# PIC32CX0525SG12144 register map
Vendor: Microchip Technology; Series: 0525SG12; File version: 0
CPU: CM4 r1p0, little endian, no MPU, no FPU, 3 interrupt priority bits, 172 interrupts
Registers are 32-bit, read-write, reset 0x0 unless marked. A register's access mark holds for its fields unless they carry their own. Offsets are from the block's base; [hi:lo] are bit positions.

## PS2_0 — The four PS/2 Ports implementation eliminates the need to bit bang I/O ports to generate PS/2 traffic
Base 0x40009000; register names take the prefix PS2_
Same registers: PS2_1 0x40009040
0x00 TX_DATA wo — Writes to bits 7:0 of this register start a transmission of the data in this register to the peripheral
0x00 RX_DATA ro reset 0xFF — Data received from a peripheral are recorded in this register in bits 7:0.
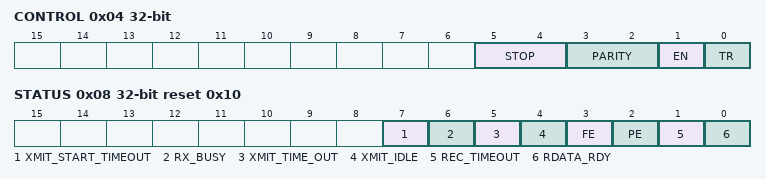
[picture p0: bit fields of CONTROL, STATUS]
0x04 CONTROL — PS2 Control Register
  [5:4] STOP — 00b=Receiver expects an active high stop bit. 01b=Receiver expects an active low stop bit. 10b=Receiver ignores the level of the Stop bit (11th bit is not interpreted as a stop bit). 11b=Reserved.
  [3:2] PARITY — 00b=Receiver expects Odd Parity (default). 01b=Receiver expects Even Parity. 10b=Receiver ignores level of the parity bit (10th bit is not interpreted as a parity bit). 11b=Reserved
  [1] EN — PS/2 Enable. 0=The PS/2 state machine is disabled. 1=The PS/2 state machine is enabled.
  [0] TR — PS/2 Transmit/Receive. 0=The P2/2 channel is enabled to receive data. 1=The PS2 channel is enabled to transmit data.
0x08 STATUS reset 0x10 — PS2 Status Register
  [7] XMIT_START_TIMEOUT — Transmit Start Timeout. 0=No transmit start timeout detected. 1=A start bit was not received within 25 ms following the transmit start event. The transmit start bit time-out condition is also indicated by the XMIT_TIMEOUT bit.
  [6] RX_BUSY — Receive Channel Busy. 0=The channel is idle. 1=The channel is actively receiving PS/2 data
  [5] XMIT_TIME_OUT — Transmitter Time-out. When the XMIT_TIMEOUT bit is set, the PS2_T/R bit is held clear, the PS/2 channel's CLK line is pulled low for a minimum of 300us until the PS/2 Status register is read.
  [4] XMIT_IDLE — Transmitter Idle. 0=The channel is actively transmitting PS/2 data. 1=The channel is not transmitting. A low to high transition on this bit generates a PS2 Activity interrupt.
  [3] FE — Framing Error
  [2] PE — Parity Error
  [1] REC_TIMEOUT — Receive Timeout. The REC_TIMEOUT bit is cleared when the Status Register is read. A low to high transition on this bit generates a PS2 Activity interrupt. (R/WC)
  [0] RDATA_RDY — Receive Data Ready. Reading the Receive Register clears this bit. A low to high transition on this bit generates a PS2 Activity interrupt.

## TFDP — The TFDP serially transmits EC-originated diagnostic vectors to an external debug trace system.
Base 0x40008C00
0x00 MSDATA 8-bit — Debug data to be shifted out on the TFDP Debug port. While data is being shifted out, the Host Interface will 'hold-off' additional writes to the data register until the transfer is complete.
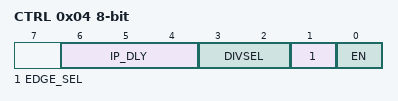
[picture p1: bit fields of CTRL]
0x04 CTRL 8-bit — Debug Control Register
  [6:4] IP_DLY — Inter-packet Delay. The delay is in terms of TFDP Debug output clocks.
  [3:2] DIVSEL — Clock Divider Select.
  [1] EDGE_SEL — 1= Data is shifted out on the falling edge of the debug clock, 0= Data is shifted out on the rising edge of the debug clock (Default)
  [0] EN — Enable. 1=Clock enabled, 0=Clock is disabled (Default)

## PORT_80_DEBUG0 — Diagnostic data is written by the Host Interface to the Port 80 BIOS Debug Port
Base 0x400F8000; register names take the prefix PORT_80_DEBUG_
Same registers: PORT_80_DEBUG1 0x400F8400
0x00 HOST_DATA wo
  [7:0] H_DAT — This is the host data.
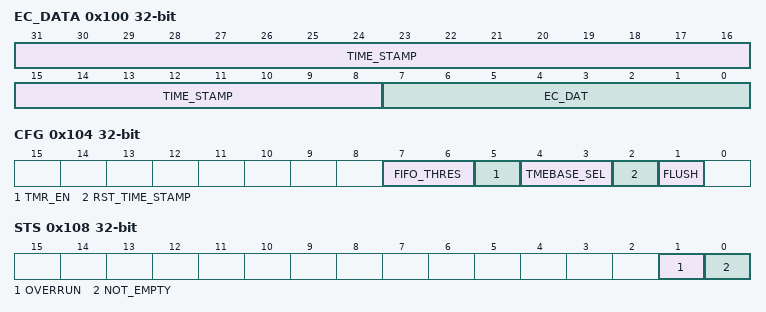
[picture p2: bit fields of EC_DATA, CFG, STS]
0x100 EC_DATA
  [31:8] TIME_STAMP — This is the time stamp.
  [7:0] EC_DAT — This is the EC data.
0x104 CFG — Configuration Register.
  [7:6] FIFO_THRES — This field determines the threshold for the Port 80 BIOS Debug Port Interrupts: 3=14 entry threshold; 2=8 entry threshold; 1=4 entry threshold; 0=1 entry threshold.
  [5] TMR_EN — When the TIMER_ENABLE bit is 1, the 24-bit Timer is actively counting at a rate determined by the TIMEBASE_SELECT bits. When the TIMER ENABLE bit is 0, counting is stopped.
  [4:3] TMEBASE_SEL — These bits determine the clock for the 24-bit Timer: 3=48MHz/64; 2=48MHz/32; 1=48MHz/16; 0=48MHz/8.
  [2] RST_TIME_STAMP — When this field is written with a 1, the 24-bit Timer is reset to 0. Writing zero to the Count Register has the same effect. Writes of a 0 to this field have no effect. Reads always return 0.
  [1] FLUSH — When this field is written with a 1, the FIFO is flushed. Writes of a 0 to this field have no effect. Reads always return 0.
0x108 STS ro — Status Register
  [1] OVERRUN — The OVERRUN bit is 1 when the host writes the Host Data Register when the FIFO is full.
  [0] NOT_EMPTY — The NOT EMPTY bit is 1 when there is data in the FIFO. The NOT EMPTY bit is 0 when the FIFO is empty.
0x10C CNT — Count Register
  [31:8] CNT — Writes load data into the 24-bit Timer. Reads return the 24-bit Timer current value.
0x330 ACTIVATE
  [0] ACT — When this bit is asserted 1, the block is enabled. When this bit is 0, writes by the Host interface to the Host Data Register are not claimed, the FIFO is flushed, the 24-bit Timer is reset, and the timer clock is stopped. Control bits in the Configuration Register are not affected by the state of ACTIVATE.
